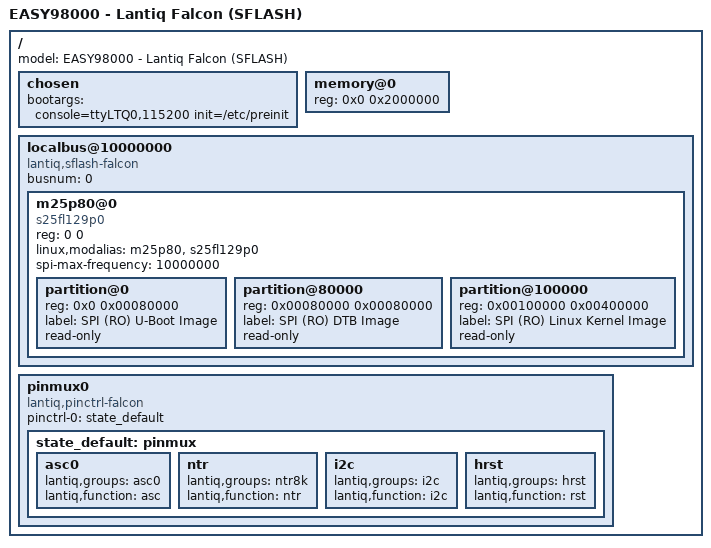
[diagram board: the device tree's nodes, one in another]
/dts-v1/;

/include/ "falcon.dtsi"

/ {
	model = "EASY98000 - Lantiq Falcon (SFLASH)";

	chosen {
		bootargs = "console=ttyLTQ0,115200 init=/etc/preinit";
	};

	memory@0 {
		reg = <0x0 0x2000000>;
	};
	
	localbus@10000000 {
		#address-cells = <1>;
		#size-cells = <1>;
		compatible = "lantiq,sflash-falcon", "simple-bus";
		busnum = <0>;

		m25p80@0 {
			#address-cells = <1>;
			#size-cells = <1>;
			compatible = "s25fl129p0";
			reg = <0 0>;
			linux,modalias = "m25p80", "s25fl129p0";
			spi-max-frequency = <10000000>;

			partition@0 {
				reg = <0x0 0x00080000>;
				label = "SPI (RO) U-Boot Image";
				read-only;
			};
	
			partition@80000 {
				reg = <0x00080000 0x00080000>;
				label = "SPI (RO) DTB Image";
				read-only;
			};

			partition@100000 {
				reg = <0x00100000 0x00400000>;
				label = "SPI (RO) Linux Kernel Image";
				read-only;
			};
		};
	};

	pinmux0 {
		compatible = "lantiq,pinctrl-falcon";
		pinctrl-names = "default";
		pinctrl-0 = <&state_default>;

		state_default: pinmux {
			asc0 {
				lantiq,groups = "asc0";
				lantiq,function = "asc";
			};
			ntr {
				lantiq,groups = "ntr8k";
				lantiq,function = "ntr";
			};
			i2c {
				lantiq,groups = "i2c";
				lantiq,function = "i2c";
			};
			hrst {
				lantiq,groups = "hrst";
				lantiq,function = "rst";
			};
		};
	};
};
